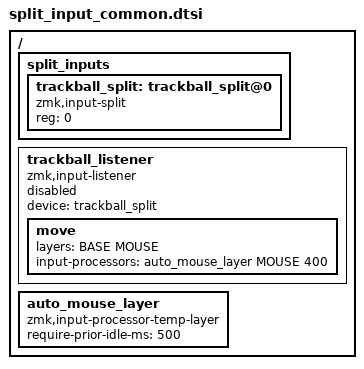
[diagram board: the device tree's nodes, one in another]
#include <dt-bindings/zmk/matrix_transform.h>
#include <input/processors.dtsi>

#define BASE 0
#define FUNCTION 1
#define NUM 2
#define ARROW 3
#define MOUSE 4
#define SCROLL 5
#define BT 6
#define Num_FN 7

/ {
  split_inputs {
    #address-cells = <1>;
    #size-cells = <0>;

    trackball_split: trackball_split@0 {
      compatible = "zmk,input-split";
      reg = <0>;
    };
  };

  trackball_listener: trackball_listener {
    compatible = "zmk,input-listener";
    status = "disabled";
    device = <&trackball_split>;

    move {
      layers = <BASE MOUSE>;
      input-processors = <&auto_mouse_layer MOUSE 400>;
    };
  };

  auto_mouse_layer: auto_mouse_layer {
    compatible = "zmk,input-processor-temp-layer";
    #input-processor-cells = <2>;
    require-prior-idle-ms = <500>;
  };
};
